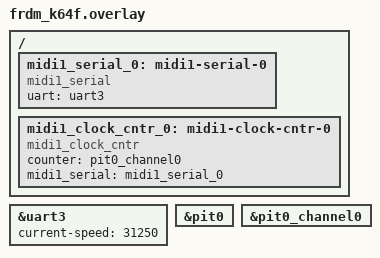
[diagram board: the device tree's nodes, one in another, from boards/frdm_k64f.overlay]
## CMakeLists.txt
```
# SPDX-License-Identifier: Apache-2.0

# MIDI 1.0 Clock Generator Sample
cmake_minimum_required(VERSION 3.20.0)

find_package(Zephyr REQUIRED HINTS $ENV{ZEPHYR_BASE})
project(midi1_clock_generator)

target_sources(app PRIVATE src/main.c)
```

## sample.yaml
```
# SPDX-License-Identifier: Apache-2.0

sample:
  name: MIDI 1.0 Clock Generator
tests:
  sample.midi1_clock_gen:
    platform_allow:
      - frdm_k64f
      - frdm_mcxc242
    harness: console
    harness_config:
      type: one_line
      regex:
        - "Clock running: (.*) BPM"
```

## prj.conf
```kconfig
# SPDX-License-Identifier: Apache-2.0

# MIDI 1.0 Clock Generator Configuration
CONFIG_MIDI1_CLOCK_CNTR=y
CONFIG_LOG=y
CONFIG_MIDI1_SERIAL=y
CONFIG_MIDI1_HARMONIC=y
```

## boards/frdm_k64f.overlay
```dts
/*
 * SPDX-License-Identifier: Apache-2.0
 */

/**
 * @file frdm_k64f.overlay
 * @brief overlay for MIDI1 clock generator
 * @author Jan-Willem Smaal <usenet@gispen.org>
 */

/ {
	midi1_serial_0: midi1-serial-0 {
		compatible = "midi1_serial";
		uart = <&uart3>;
		status = "okay";
	};

	midi1_clock_cntr_0: midi1-clock-cntr-0 {
		compatible = "midi1_clock_cntr";
		counter = <&pit0_channel0>;
		midi1_serial = <&midi1_serial_0>;
		status = "okay";
	};
};

&uart3 {
	status = "okay";
	/* MIDI baud rate */
	current-speed = <31250>;
};

&pit0 {
	status = "okay";
};

&pit0_channel0 {
	status = "okay";
};

/* EOF */
```

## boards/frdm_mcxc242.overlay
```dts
/*
 * SPDX-License-Identifier: Apache-2.0
 */

/**
 * @file frdm_mcxc242.overlay
 * @brief overlay for MIDI1 clock generator on MCXC242
 * @author Jan-Willem Smaal <usenet@gispen.org>
 */

/ {
	midi1_serial_0: midi1-serial-0 {
		compatible = "midi1_serial";
		uart = <&lpuart0>;
		status = "okay";
	};

	midi1_clock_cntr_0: midi1-clock-cntr-0 {
		compatible = "midi1_clock_cntr";
		counter = <&pit0_channel0>;
		midi1_serial = <&midi1_serial_0>;
		status = "okay";
	};
};

&lpuart0 {
	status = "okay";
	current-speed = <31250>;
};

&pit0 {
	status = "okay";
};

&pit0_channel0 {
	status = "okay";
};

/* EOF */
```

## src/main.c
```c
/*
 * SPDX-License-Identifier: Apache-2.0
 */

/**
 * @file main.c
 * @brief MIDI 1.0 Clock Generator Sample Application
 *
 * This sample demonstrates how to use the midi1_clock_cntr driver
 * to generate a 24 PPQN (Pulses Per Quarter Note) MIDI timing clock.
 */

#include <zephyr/kernel.h>
#include <zephyr/device.h>
#include <zephyr/drivers/midi/midi1.h>
#include <zephyr/drivers/midi/midi1_clock_cntr.h>
#include <zephyr/logging/log.h>

LOG_MODULE_REGISTER(midi1_clock_gen_sample, LOG_LEVEL_INF);

/* 120.00 BPM scaled by 100 */
#define TARGET_BPM 12000

int main(void)
{
	const struct device *clk_dev = DEVICE_DT_GET_ANY(midi1_clock_cntr);
	char bpm_str[16];

	if (clk_dev == NULL) {
		LOG_ERR("No midi1-clock-cntr device found in devicetree");
		return -ENODEV;
	}

	if (!device_is_ready(clk_dev)) {
		LOG_ERR("MIDI clock device %s is not ready", clk_dev->name);
		return -ENODEV;
	}

	sbpm_to_str(TARGET_BPM, bpm_str, sizeof(bpm_str));
	LOG_INF("Starting MIDI Clock Generator at %s BPM", bpm_str);

	/* Start generating the clock at the specified BPM */
	midi1_clock_cntr_gen(clk_dev, TARGET_BPM);

	while (1) {
		uint16_t current_bpm = midi1_clock_cntr_get_sbpm(clk_dev);
		sbpm_to_str(current_bpm, bpm_str, sizeof(bpm_str));
		LOG_INF("Clock running: %s BPM", bpm_str);
		k_sleep(K_SECONDS(5));
	}

	return 0;
}
```
